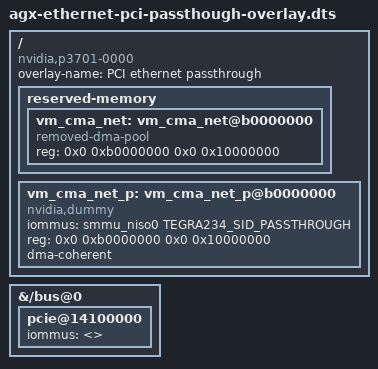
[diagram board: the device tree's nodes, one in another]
/*
 * Copyright 2022-2025 TII (SSRC) and the Ghaf contributors
 * SPDX-License-Identifier: CC-BY-SA-4.0
 */

/dts-v1/;
/plugin/;

#include <dt-bindings/clock/tegra234-clock.h>
#include <dt-bindings/reset/tegra234-reset.h>
#include <dt-bindings/power/tegra234-powergate.h>
#include <dt-bindings/memory/tegra234-mc.h>
#include <dt-bindings/interrupt-controller/irq.h>
#include <dt-bindings/interrupt-controller/arm-gic.h>

/ {
    overlay-name = "PCI ethernet passthrough";
    compatible = "nvidia,p3701-0000";

    fragment@0 {
        target-path = "/";
        __overlay__ {
            reserved-memory {
                vm_cma_net: vm_cma_net@b0000000 {
                    compatible = "removed-dma-pool";
                    reg = <0x0 0xb0000000 0x0 0x10000000>;
                    status = "okay";
                };
	    };

	    vm_cma_net_p: vm_cma_net_p@b0000000 {
                compatible = "nvidia,dummy";
                iommus = <&smmu_niso0 TEGRA234_SID_PASSTHROUGH>;
                reg = <0x0 0xb0000000 0x0 0x10000000>;
                dma-coherent;
                status = "okay";
            };
	};
    };

    fragment@1 {
        target-path = "/bus@0";
        __overlay__ {
            pcie@14100000 {
                iommus = <>;
            };
        };
    };

};
